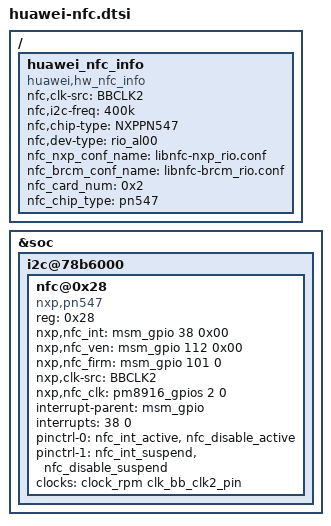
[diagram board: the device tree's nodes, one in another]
 / {
        huawei_nfc_info {
	        compatible = "huawei,hw_nfc_info";
	        nfc,clk-src = "BBCLK2";
	        nfc,i2c-freq = "400k";
	        nfc,chip-type = "NXPPN547";
	        nfc,dev-type = "rio_al00";
		nfc_nxp_conf_name = "libnfc-nxp_rio.conf";
		nfc_brcm_conf_name = "libnfc-brcm_rio.conf";
		nfc_card_num = <0x2>;
		nfc_chip_type = "pn547";
	        status = "ok";
        };
};

&soc {
       i2c@78b6000 { /* BLSP1 QUP2 */
		nfc@0x28 {
			compatible = "nxp,pn547";
			status = "ok";
			reg = <0x28>;
			nxp,nfc_int = <&msm_gpio 38 0x00>;
			nxp,nfc_ven = <&msm_gpio 112 0x00>;
			nxp,nfc_firm = <&msm_gpio 101 0>;
			nxp,clk-src = "BBCLK2";	
			nxp,nfc_clk = <&pm8916_gpios 2 0>;			
			interrupt-parent = <&msm_gpio>;
			interrupts = <38 0>; /*1 = low-to-high edge triggered
     		                                 2 = high-to-low edge triggered
     		                                 4 = active high level-sensitive
     		                                 8 = active low level-sensitive */
			interrupt-names = "nfc_irq";
			pinctrl-names = "nfc_active","nfc_suspend";
			pinctrl-0 = <&nfc_int_active &nfc_disable_active>;
			pinctrl-1 = <&nfc_int_suspend &nfc_disable_suspend>;
			clocks = <&clock_rpm clk_bb_clk2_pin>;
			clock-names = "pn547_clk";

		};
	};
};
